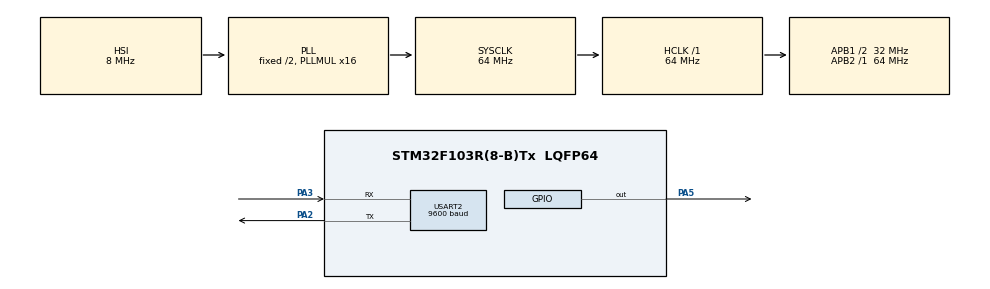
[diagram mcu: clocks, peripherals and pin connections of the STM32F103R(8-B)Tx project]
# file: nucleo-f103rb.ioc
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Mcu.Family=STM32F1
RCC.APB1CLKDivider=RCC_HCLK_DIV2
USART2.BaudRate=9600
RCC.SYSCLKSource=RCC_SYSCLKSOURCE_PLLCLK
ProjectManager.StackSize=0x400
PA13.Signal=SYS_JTMS-SWDIO
PA3.Mode=Asynchronous
ProjectManager.TargetToolchain=STM32CubeIDE
RCC.HCLKFreq_Value=64000000
RCC.APB2TimFreq_Value=64000000
RCC.USBFreq_Value=64000000
RCC.AHBFreq_Value=64000000
PA5.Signal=GPIO_Output
board=custom
RCC.PLLMUL=RCC_PLL_MUL16
RCC.APB2Freq_Value=64000000
PA14.Mode=Serial_Wire
PA13.Mode=Serial_Wire
Mcu.Name=STM32F103R(8-B)Tx
PA2.Signal=USART2_TX
RCC.SYSCLKFreq_VALUE=64000000
Mcu.Package=LQFP64
USART2.VirtualMode=VM_ASYNC
PA14.Signal=SYS_JTCK-SWCLK
ProjectManager.HeapSize=0x200
NVIC.PriorityGroup=NVIC_PRIORITYGROUP_4
RCC.APB1TimFreq_Value=64000000
PA2.Mode=Asynchronous
RCC.APB1Freq_Value=32000000
PA3.Signal=USART2_RX

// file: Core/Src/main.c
/* USER CODE BEGIN Header */
/**
  ******************************************************************************
  * @file           : main.c
  * @brief          : Main program body
  ******************************************************************************
  * @attention
  *
  * <h2><center>&copy; Copyright (c) 2021 STMicroelectronics.
  * All rights reserved.</center></h2>
  *
  * This software component is licensed by ST under BSD 3-Clause license,
  * the "License"; You may not use this file except in compliance with the
  * License. You may obtain a copy of the License at:
  *                        opensource.org/licenses/BSD-3-Clause
  *
  ******************************************************************************
  */
/* USER CODE END Header */
#include "main.h"
#include "usart.h"
#include "gpio.h"

#include <stdio.h>

void SystemClock_Config(void);

/* USER CODE BEGIN 0 */

int _write(int32_t file, uint8_t *ptr, int32_t len){
    HAL_UART_Transmit(&huart2, ptr, len, 10);
    return len;
}

/* USER CODE END 0 */

int main(void)
{

  /* MCU Configuration--------------------------------------------------------*/

  /* Reset of all peripherals, Initializes the Flash interface and the Systick. */
  HAL_Init();

  /* Configure the system clock */
  SystemClock_Config();

  /* Initialize all configured peripherals */
  MX_GPIO_Init();
  MX_USART2_UART_Init();

  /* Infinite loop */
  while (1)
  {

    /* USER CODE BEGIN 3 */

	  HAL_GPIO_WritePin(GPIOA, GPIO_PIN_5, GPIO_PIN_RESET);
	  HAL_Delay(100);
	  HAL_GPIO_WritePin(GPIOA, GPIO_PIN_5, GPIO_PIN_SET);
	  HAL_Delay(100);

	  printf("hello\n");

  }
  /* USER CODE END 3 */
}

void SystemClock_Config(void)
{
  RCC_OscInitTypeDef RCC_OscInitStruct = {0};
  RCC_ClkInitTypeDef RCC_ClkInitStruct = {0};

  /** Initializes the RCC Oscillators according to the specified parameters
  * in the RCC_OscInitTypeDef structure.
  */
  RCC_OscInitStruct.OscillatorType = RCC_OSCILLATORTYPE_HSI;
  RCC_OscInitStruct.HSIState = RCC_HSI_ON;
  RCC_OscInitStruct.HSICalibrationValue = RCC_HSICALIBRATION_DEFAULT;
  RCC_OscInitStruct.PLL.PLLState = RCC_PLL_ON;
  RCC_OscInitStruct.PLL.PLLSource = RCC_PLLSOURCE_HSI_DIV2;
  RCC_OscInitStruct.PLL.PLLMUL = RCC_PLL_MUL16;
  if (HAL_RCC_OscConfig(&RCC_OscInitStruct) != HAL_OK)
  {
    Error_Handler();
  }
  /** Initializes the CPU, AHB and APB buses clocks
  */
  RCC_ClkInitStruct.ClockType = RCC_CLOCKTYPE_HCLK|RCC_CLOCKTYPE_SYSCLK
                              |RCC_CLOCKTYPE_PCLK1|RCC_CLOCKTYPE_PCLK2;
  RCC_ClkInitStruct.SYSCLKSource = RCC_SYSCLKSOURCE_PLLCLK;
  RCC_ClkInitStruct.AHBCLKDivider = RCC_SYSCLK_DIV1;
  RCC_ClkInitStruct.APB1CLKDivider = RCC_HCLK_DIV2;
  RCC_ClkInitStruct.APB2CLKDivider = RCC_HCLK_DIV1;

  if (HAL_RCC_ClockConfig(&RCC_ClkInitStruct, FLASH_LATENCY_2) != HAL_OK)
  {
    Error_Handler();
  }
}

void Error_Handler(void)
{
  __disable_irq();
  while (1)
  {
  }
}

/************************ (C) COPYRIGHT STMicroelectronics *****END OF FILE****/
